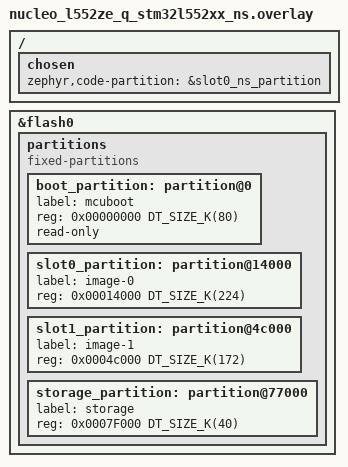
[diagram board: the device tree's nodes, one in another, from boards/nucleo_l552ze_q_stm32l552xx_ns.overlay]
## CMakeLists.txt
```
#
# Copyright (c) 2021 Nordic Semiconductor ASA
#
# SPDX-License-Identifier: Apache-2.0
#

cmake_minimum_required(VERSION 3.20.0)

find_package(Zephyr REQUIRED HINTS $ENV{ZEPHYR_BASE})

project(tfm_regression_test)

target_sources(app PRIVATE src/main.c)

get_target_property(TFM_BINARY_DIR           tfm TFM_BINARY_DIR)
get_target_property(TFM_NS_BIN_FILE          tfm TFM_NS_BIN_FILE)
get_target_property(TFM_NS_HEX_FILE          tfm TFM_NS_HEX_FILE)
get_target_property(TFM_NS_SIGNED_BIN_FILE   tfm TFM_NS_SIGNED_BIN_FILE)

get_target_property(TFM_TOOLCHAIN_PATH       tfm TFM_TOOLCHAIN_PATH)
get_target_property(TFM_TOOLCHAIN_PREFIX     tfm TFM_TOOLCHAIN_PREFIX)
get_target_property(TFM_TOOLCHAIN_NS_FILE    tfm TFM_TOOLCHAIN_NS_FILE)

set(TFM_TEST_REPO_PATH ${ZEPHYR_TRUSTED_FIRMWARE_M_MODULE_DIR}/../tf-m-tests)

set(TFM_TEST_DIR         "${TFM_TEST_REPO_PATH}/tests_reg/test/secure_regression")
set(TFM_TEST_CONFIG_FILE "${TFM_TEST_REPO_PATH}/tests_reg/test/config/config.cmake")

set_property(TARGET zephyr_property_target
             APPEND PROPERTY TFM_CMAKE_OPTIONS
             -DCONFIG_TFM_TEST_DIR=${TFM_TEST_DIR}
)

set_property(TARGET zephyr_property_target
             APPEND PROPERTY TFM_CMAKE_OPTIONS
             -DCONFIG_TFM_TEST_CONFIG_FILE=${TFM_TEST_CONFIG_FILE}
)

include(ExternalProject)

ExternalProject_Add(tfm_regression_test_app
    SOURCE_DIR ${TFM_TEST_REPO_PATH}/tests_reg
    BINARY_DIR ${PROJECT_BINARY_DIR}/tfm_ns
    CONFIGURE_COMMAND
        ${CMAKE_COMMAND}
                -G ${CMAKE_GENERATOR}
                -S ${TFM_TEST_REPO_PATH}/tests_reg
                -B ${PROJECT_BINARY_DIR}/tfm_ns
                -DCONFIG_SPE_PATH=${TFM_BINARY_DIR}/api_ns
                -DTFM_TOOLCHAIN_FILE=cmake/${TFM_TOOLCHAIN_NS_FILE}
                -DCROSS_COMPILE=${TFM_TOOLCHAIN_PATH}/${TFM_TOOLCHAIN_PREFIX}
                -DQCBOR_PATH${QCBOR_PATH_TYPE}=${CONFIG_TFM_QCBOR_PATH}
                -DCMAKE_BUILD_TYPE=RelWithDebInfo
    BUILD_COMMAND ${CMAKE_COMMAND} --build .
    INSTALL_COMMAND ""
    BUILD_ALWAYS True
    USES_TERMINAL_BUILD True
    WORKING_DIRECTORY ${PROJECT_BINARY_DIR}/tfm_ns
    DEPENDS tfm
    BUILD_BYPRODUCTS
        ${TFM_NS_HEX_FILE}
        ${TFM_NS_BIN_FILE}
        ${TFM_NS_SIGNED_BIN_FILE}
)

add_dependencies(app tfm_regression_test_app)
```

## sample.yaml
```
common:
  tags:
    - trusted-firmware-m
    - mcuboot
  modules:
    - psa-arch-tests
  platform_allow:
    - nrf5340dk/nrf5340/cpuapp/ns
    - nrf9160dk/nrf9160/ns
    - nrf9161dk/nrf9161/ns
    - v2m_musca_s1/musca_s1/ns
  integration_platforms:
    - nrf5340dk/nrf5340/cpuapp/ns
  harness: console
  harness_config:
    type: multi_line
    regex:
      - "Non-Secure system starting..."
      - "\\#\\#\\#\\# Execute test suites for the Non-secure area \\#\\#\\#\\#"
      - "\\*\\*\\* End of Non-secure test suites \\*\\*\\*"

sample:
  name: "TFM Regression Test"

tests:
  sample.tfm.regression_ipc_lvl1:
    extra_args:
      - CONFIG_TFM_IPC=y
      - CONFIG_TFM_ISOLATION_LEVEL=1
    timeout: 200

  sample.tfm.regression_ipc_lvl2:
    timeout: 200

  sample.tfm.regression_sfn:
    extra_args:
      - CONFIG_TFM_SFN=y
      - CONFIG_TFM_ISOLATION_LEVEL=1
    timeout: 200
```

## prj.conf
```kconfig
#
# Copyright (c) 2021 Nordic Semiconductor ASA
#
# SPDX-License-Identifier: Apache-2.0
#

CONFIG_BUILD_WITH_TFM=y
CONFIG_TFM_PROFILE_TYPE_NOT_SET=y
CONFIG_TFM_USE_NS_APP=y
CONFIG_TFM_REGRESSION_S=y
CONFIG_TFM_REGRESSION_NS=y

# Regression tests are included if a related secure partition is enabled.
CONFIG_TFM_PARTITION_PROTECTED_STORAGE=y
CONFIG_TFM_PARTITION_INTERNAL_TRUSTED_STORAGE=y
CONFIG_TFM_PARTITION_CRYPTO=y
CONFIG_TFM_PARTITION_INITIAL_ATTESTATION=n
CONFIG_TFM_PARTITION_PLATFORM=y

# Enable IPC mode and isolation level 2 by default
CONFIG_TFM_IPC=y
CONFIG_TFM_ISOLATION_LEVEL=2
```

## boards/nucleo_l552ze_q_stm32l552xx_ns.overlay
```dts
/*
 * Copyright (c) 2023 STMicroelectronics
 *
 * SPDX-License-Identifier: Apache-2.0
 */


 /* This partition table could be used along with TFM configuration:
  * - TEST_S=ON (REGRESSION)
  * - TFM_PSA_API=ON (IPC)
  *
  */

/ {
	chosen {
		zephyr,code-partition = &slot0_ns_partition;
	};
};


/delete-node/ &slot1_partition;
/delete-node/ &slot1_ns_partition;

&flash0 {

	partitions {
		compatible = "fixed-partitions";
		#address-cells = <1>;
		#size-cells = <1>;

		boot_partition: partition@0 {
			label = "mcuboot";
			reg = <0x00000000 DT_SIZE_K(80)>;
			read-only;
		};
		/* Secure image primary slot */
		slot0_partition: partition@14000 {
			label = "image-0";
			reg = <0x00014000 DT_SIZE_K(224)>;
		};
		/* Non-secure image primary slot */
		slot1_partition: partition@4c000 {
			label = "image-1";
			reg = <0x0004c000 DT_SIZE_K(172)>;
		};
		/*
		 * The flash starting at 0x7F000 and ending at
		 * 0x80000 is reserved for the application.
		 */
		storage_partition: partition@77000 {
			label = "storage";
			reg = <0x0007F000 DT_SIZE_K(40)>;
		};
	};
};
```

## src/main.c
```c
/*
 * Copyright (c) 2021 Nordic Semiconductor ASA.
 *
 * SPDX-License-Identifier: Apache-2.0
 */

#include <zephyr/kernel.h>

int main(void)
{
	printk("Should not be printed, expected TF-M's NS application to be run instead.\n");
	k_panic();

	for (;;) {
	}
}
```
